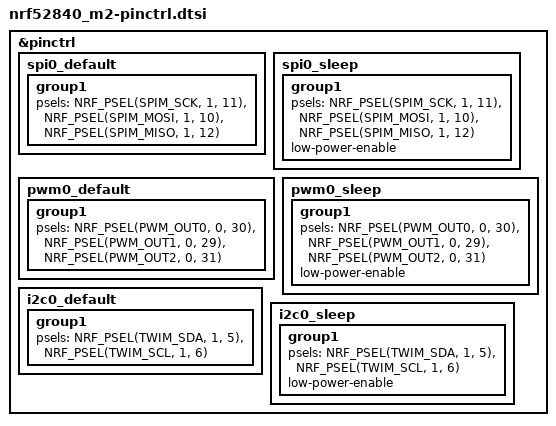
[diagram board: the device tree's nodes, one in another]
&pinctrl {
    /* configuration for spi0 device, default state */
    spi0_default: spi0_default {
        /* node name is arbitrary */
        group1 {
            /* main role: configure P1.11 as SPI clock, P0.02 as SPI MOSI, P0.03 as SPI MISO */
            psels = <NRF_PSEL(SPIM_SCK, 1, 11)>,
                    <NRF_PSEL(SPIM_MOSI, 1, 10)>,
                    <NRF_PSEL(SPIM_MISO, 1, 12)>;
        };
    };

    /* configuration for spi0 device, sleep state */
    spi0_sleep: spi0_sleep {
        group1 {
            /* main role: configure P1.11 as SPI clock, P0.02 as SPI MOSI, P0.03 as SPI MISO */
            psels = <NRF_PSEL(SPIM_SCK, 1, 11)>,
                    <NRF_PSEL(SPIM_MOSI, 1, 10)>,
                    <NRF_PSEL(SPIM_MISO, 1, 12)>;
            low-power-enable;
        };
    };

    /* configuration for pwm device, default state */
    pwm0_default: pwm0_default {
        group1 {
            psels = <NRF_PSEL(PWM_OUT0, 0, 30)>, // LED 0 (red)
                    <NRF_PSEL(PWM_OUT1, 0, 29)>, // LED 1 (green)
                    <NRF_PSEL(PWM_OUT2, 0, 31)>; // LED 2 (blue)
        };
    };
    pwm0_sleep: pwm0_sleep {
        group1 {
              psels = <NRF_PSEL(PWM_OUT0, 0, 30)>, // LED 0
                      <NRF_PSEL(PWM_OUT1, 0, 29)>, // LED 1
                      <NRF_PSEL(PWM_OUT2, 0, 31)>; // LED 2
            low-power-enable;
        };
    };

    /* configuration for i2c0 device, default state */
    i2c0_default: i2c0_default {
        group1 {
            psels = <NRF_PSEL(TWIM_SDA, 1, 5)>,
                <NRF_PSEL(TWIM_SCL, 1, 6)>;
        };
    };

    i2c0_sleep: i2c0_sleep {
        group1 {
            psels = <NRF_PSEL(TWIM_SDA, 1, 5)>,
                <NRF_PSEL(TWIM_SCL, 1, 6)>;
            low-power-enable;
        };
    };
};
